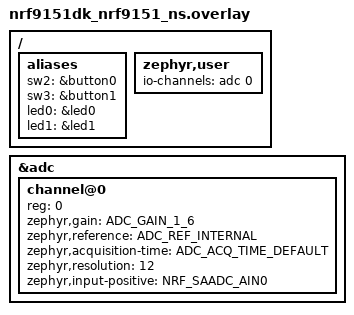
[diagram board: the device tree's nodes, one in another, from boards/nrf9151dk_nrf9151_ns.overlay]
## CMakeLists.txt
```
cmake_minimum_required(VERSION 3.20.0)
find_package(Zephyr REQUIRED HINTS $ENV{ZEPHYR_BASE})

project(iot_Celluar_proj)

target_sources(app 
    PRIVATE 
        src/main.c
        src/socket_setup.c
        src/coap_client.c
        src/modem_lte.c
        src/gnss.c
        src/agnss.c
        src/nodecore_lib/nodecore_event.c
        src/adc_input.c
    )
```

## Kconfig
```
menu "Cellular Project"

config COAP_SERVER_HOSTNAME
    string "CoAP server hostname"

config COAP_SERVER_PORT
    int "CoAP server port"
    default 5683

config FIRMARE_VERSION
    string "Firmware version"
    default "1.0.0"


config COAP_TX_RESOURCE
    string "CoAP resource - this is the TX channel of the board"
    default "large-update"

config COAP_RX_RESOURCE
    string "CoAP resource - this is the RX channel of the board"
    default "validate"

config COAP_DEVICE_ID
    int "CoAP device id - To know which sensor is speaking"
    default 200001

# - Define PSK Identity configurations
config COAP_DEVICE_NAME
    string "Device resource name - this will be the device name on the CoAP server"
    default "cali.test.nrf91"

config COAP_SERVER_PSK
    string "Server PSK"
    default "2e666f726e69756d"

config DK
	bool "nRF9151 DK, nRF9161 DK or nRF9160 DK"
	default y if (BOARD_NRF9160DK_NRF9160_NS) || (BOARD_NRF9161DK_NRF9161_NS) || (BOARD_NRF9151DK_NRF9151_NS)

config THINGY
	bool "Thingy:91 X or Thingy:91"
	default y if (BOARD_THINGY91_NRF9160_NS) || (BOARD_THINGY91X_NRF9151_NS)


config GNSS_PERIODIC_INTERVAL
    int "Fix interval for periodic GPS fixes"
    range 10 65535
    default 15
    help
        Fix interval (in secounds) for periodic fixes.

config DTLS_SEC_TAG
    int "Indicate where the sec tag is and so the modem knows"
    default 12

config GNSS_PERIODIC_TIMEOUT
    int "Fix timeout for periodic GPS fixes"
    range 0 65535
    default 120
    help
       Fix timeout (in secounds) for periodic fixes.
       If set to zero, GNSS is allowed to run indefinietly unttil a valid PVT estimate is produced.

endmenu

menu "Zephyr Kernel"
source "Kconfig.zephyr"
endmenu
```

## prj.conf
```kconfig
# Logging
CONFIG_LOG=y

# Button and LED support
CONFIG_DK_LIBRARY=y

# Newlib
CONFIG_NEWLIB_LIBC=y

# Network
CONFIG_NETWORKING=y
CONFIG_NET_NATIVE=n
CONFIG_NET_SOCKETS=y
CONFIG_NET_SOCKETS_OFFLOAD=y
CONFIG_POSIX_API=y

# Memory
CONFIG_HEAP_MEM_POOL_SIZE=19000
CONFIG_MAIN_STACK_SIZE=8192
CONFIG_SYSTEM_WORKQUEUE_STACK_SIZE=8192

# Modem library
# Enable the nRF Modem library
CONFIG_NRF_MODEM_LIB=y

# Enable the LTE link controller library
CONFIG_LTE_LINK_CONTROL=y

# AT Host library 
CONFIG_AT_HOST_LIBRARY=y

# Enables interrupt support for UART, that the AT Host library can print asynchronously to the console.
CONFIG_UART_INTERRUPT_DRIVEN=y

# Enable this 2 enable printing floating-point numbers to console.
CONFIG_NEWLIB_LIBC_FLOAT_PRINTF=y
CONFIG_FPU=y

#----------------------------------- CoAP ---------------------------------------------------------------
# Enable the CoAP library
CONFIG_COAP=y

# Configure the CoAP server hostname
CONFIG_COAP_SERVER_HOSTNAME="188.149.134.45" #publika hemma

# Configure the CoAP server port
CONFIG_COAP_SERVER_PORT=5683

# Enable the modem’s network mode for GPS --------------------------------------------------------------------------- 
CONFIG_LTE_NETWORK_MODE_LTE_M_GPS=y

# Enable eDRX and PSM
CONFIG_LTE_LC_EDRX_MODULE=y
CONFIG_LTE_LC_PSM_MODULE=y

# enable requesitng the use of eDRX
CONFIG_LTE_EDRX_REQ=y

# Requesting periodic TAU of 8 hours and an active time of 16 seconds.
CONFIG_LTE_PSM_REQ_RPTAU="00101000"
CONFIG_LTE_PSM_REQ_RAT="00001000"

# Enable NRF cloud
CONFIG_NRF_CLOUD=y
CONFIG_NRF_CLOUD_AGNSS=y
CONFIG_NRF_CLOUD_COAP=y

# Required by nRF Cloud A-GNSS
CONFIG_MODEM_INFO=y
CONFIG_MODEM_INFO_ADD_NETWORK=y
CONFIG_MODEM_INFO_ADD_DEVICE=y

# Required for nRF Cloud CoAP authentication/JWT
CONFIG_MODEM_JWT=y
CONFIG_MODEM_KEY_MGMT=y
CONFIG_NRF_CLOUD_CLIENT_ID_SRC_INTERNAL_UUID=y
CONFIG_NRF_CLOUD_CHECK_CREDENTIALS=y
CONFIG_NRF_CLOUD_SEC_TAG=16842753

# Time for JWT / nRF Cloud
CONFIG_DATE_TIME=y
CONFIG_DATE_TIME_NTP=y

# CoAP client settings for nRF Cloud CoAP
CONFIG_COAP_CLIENT_BLOCK_SIZE=1024
CONFIG_COAP_CLIENT_STACK_SIZE=6144
CONFIG_COAP_CLIENT_THREAD_PRIORITY=0
CONFIG_COAP_EXTENDED_OPTIONS_LEN_VALUE=40

CONFIG_COAP_DEVICE_ID=200001
CONFIG_ADC=y

# Aktivera PDN-biblioteket och tillåt äldre PCO-hantering för ditt Conexa-SIM
CONFIG_PDN=y
CONFIG_PDN_LEGACY_PCO=y

# Gör att modemet skickar detaljerade felhändelser (som EMM-koder) till din C-kod
CONFIG_LTE_LC_MODEM_EVENTS_MODULE=y

# Tvinga modemet att använda ditt SIM-korts specifika APN vid registrering
CONFIG_PDN_DEFAULTS_OVERRIDE=y
CONFIG_PDN_DEFAULT_APN="eapn1.net"

# Aktivera nätverks- och bandkonfiguration
CONFIG_LTE_LINK_CONTROL=y

# Korrekt binär bit-sträng för Band 3, 8 och 20 (räknat från höger till vänster)
CONFIG_LTE_LOCK_BANDS=y
CONFIG_LTE_LOCK_BAND_MASK="10000000000010000100"
```

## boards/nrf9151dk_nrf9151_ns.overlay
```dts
#include <zephyr/dt-bindings/adc/adc.h>
#include <zephyr/dt-bindings/adc/nrf-saadc.h>

/ {
    aliases {
        sw2 = &button0;
        sw3 = &button1;

        led0 = &led0;
        led1 = &led1;
    };

    zephyr,user {
        io-channels = <&adc 0>;
    };
};

&adc {
    status = "okay";
    #address-cells = <1>;
    #size-cells = <0>;

    channel@0 {
        reg = <0>;
        zephyr,gain = "ADC_GAIN_1_6";
        zephyr,reference = "ADC_REF_INTERNAL";
        zephyr,acquisition-time = <ADC_ACQ_TIME_DEFAULT>;
        zephyr,resolution = <12>;
        zephyr,input-positive = <NRF_SAADC_AIN0>;
    };
};
```

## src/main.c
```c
#include <stdio.h>
#include <ncs_version.h>

#include <zephyr/kernel.h>
#include <zephyr/logging/log.h>
#include <dk_buttons_and_leds.h>
#include "./nodecore_lib/nodecore_event.h"

#include <zephyr/random/random.h>
#include <zephyr/net/coap.h>
#include "socket_setup.h"
#include "coap_client.h"
#include "modem_lte.h"
#include "app_state.h"
#include "gnss.h"
#include "adc_input.h"

// #define TX_KEEP_ALIVE_INTERVAL 6500

LOG_MODULE_REGISTER(app, LOG_LEVEL_INF);

#define DEVICE_HEALTH_INTERVAL K_SECONDS(120)
#define DEVICE_LIFECYCLE_INTERVAL K_SECONDS(120)

#define DEVICE_STATUS_JSON_SIZE 256


app_state_t app_state = APP_STATE_INIT;

static uint8_t recv_buf[MESSAGE_SIZE];

static struct k_work_delayable device_health_work;
static struct k_work_delayable device_lifecycle_work;

static int32_t filtered_battery_mv = 0;

void device_health_start() {
    k_work_reschedule(&device_health_work, DEVICE_HEALTH_INTERVAL);
}

void device_lifecycle_start() {
    k_work_reschedule(&device_lifecycle_work, DEVICE_LIFECYCLE_INTERVAL);
}


void device_health_handler(struct k_work *work) {
        
        ARG_UNUSED(work);
        
        int err;

         // Läs den råa spänningen från ADC
        int32_t real_battery_mv = read_voltage_mv();

        if (real_battery_mv > 0) {
                if (filtered_battery_mv == 0) {
                // Första körningen någonsin: Sätt startvärdet direkt
                filtered_battery_mv = real_battery_mv;
                } else {
                // 2. TRÖGARE EMA-FILTER: 95% gammal spänning, 5% ny spänning
                // Detta kräver runt 15-20 mätningar för att flytta sig stort, 
                // vilket helt raderar ut spänningsfall från modemsändningar!
                filtered_battery_mv = ((filtered_battery_mv * 95) + (real_battery_mv * 5)) / 100;
                }
        }

        // Skicka in den globala, filtrerade spänningen
        uint8_t battery_percent = calculate_battery_percentage(filtered_battery_mv);
        // Valfritt: Lägg till en logg så du ser hur filtret jobbar i terminalen
        LOG_INF("Rå: %d mV | Filtrerad: %d mV -> %d%%", 
            real_battery_mv, filtered_battery_mv, battery_percent);

        size_t url_path_array_length = 2;
        const char* url_path_array[] = {"device", "health"};


        char text[DEVICE_STATUS_JSON_SIZE];

        int len = snprintf(
                text,
                sizeof(text),
                "{\"device_ID\": %d, \"battery_percent\": %d, \"firmware_version\": \"%s\"}",
                CONFIG_COAP_DEVICE_ID,
                battery_percent,
                CONFIG_FIRMARE_VERSION
        );

        if (len < 0 || len >= sizeof(text)) {
                LOG_ERR("Failed to format device status JSON");
                return;
        }

        LOG_INF("Device health payload: %s", text);
        LOG_INF("Device health payload length: %d", len);


        err = client_post_send((const uint8_t *)text, url_path_array, url_path_array_length);

        if(err != 0) {
                LOG_ERR("Error sendning device health!");
                return;
        }
        LOG_INF("Device health sended!");
        k_work_reschedule(&device_health_work, DEVICE_HEALTH_INTERVAL);
}


void device_lifecycle_handler(struct k_work *work) {
        
        ARG_UNUSED(work);
        
        int err;

        int32_t real_battery_mv = read_voltage_mv();
        uint8_t battery_percent = calculate_battery_percentage(real_battery_mv);
        // uint8_t battery_percent = 93;
                // LOG_INF("Faktisk batterispanning: %d mV (%d%%)", real_battery_mv, battery_percent);

        size_t url_path_array_length = 2;
        const char* url_path_array[] = {"device", "lifecycle"};


        char text[DEVICE_STATUS_JSON_SIZE];

        int len = snprintf(
                text,
                sizeof(text),
                "{\"device_ID\": %d, \"battery_percent\": %d, \"gnss_periodic_timeout\": %d, \"gnss_periodic_interval\": %d, \"firmware_version\": \"%s\"}",
                CONFIG_COAP_DEVICE_ID,
                battery_percent,
                CONFIG_GNSS_PERIODIC_TIMEOUT,
                CONFIG_GNSS_PERIODIC_INTERVAL,
                CONFIG_FIRMARE_VERSION
        );

        if (len < 0 || len >= sizeof(text)) {
                LOG_ERR("Failed to format device status JSON");
                return;
        }

        LOG_INF("Device lifecycle payload: %s", text);
        LOG_INF("Device lifecycle payload length: %d", len);


        err = client_post_send((const uint8_t *)text, url_path_array, url_path_array_length);

        if(err != 0) {
                LOG_ERR("Error sendning device lifecycle!");
                return;
        }
        LOG_INF("Device lifecycle sended!");
        k_work_reschedule(&device_lifecycle_work, DEVICE_LIFECYCLE_INTERVAL);
}

static void button_handler(uint32_t button_state, uint32_t has_changed)
{
       if(has_changed & DK_BTN1_MSK && button_state & DK_BTN1_MSK) {
                size_t url_path_array_length = 2;
                const char* url_path_array[] = {"device", "status"};

                const char text[] = "{\"status\": 1}";

                client_post_send(text, url_path_array, url_path_array_length);
        }
        
        if(has_changed & DK_BTN2_MSK && button_state & DK_BTN2_MSK) {
               
        }

}

int main(void)
{
        int err;
        int recieved;

        err = init_adc();
        if(err < 0) {
                LOG_ERR("init adc failed!");
                return -1;
        }
        LOG_INF("adc initiazled successful!");

        if (dk_leds_init() != 0) {
		LOG_ERR("Failed to initialize the LEDs Library");
                return 0;
	}

        err = modem_configure();
        if(err) {
                LOG_ERR("Failed to configure modem");
                return 0;
        }
        
        if(app_state == APP_STATE_LTE_READY) {
                dk_set_led_on(DK_LED2);
        }

        err = lte_lc_func_mode_set(LTE_LC_FUNC_MODE_ACTIVATE_GNSS);
        if(err) {
                LOG_ERR("Failed to set modem mode!");
                return 0;
        }

               if(dk_buttons_init(button_handler) != 0) {
                LOG_ERR("Failted to init buttons library");
                return 0;
        }

        if(server_resolve() != 0) {
                LOG_INF("Failted to resolve server name");
                return 0;
        }

        if(client_init() != 0) {
                LOG_INF("failed to initialize client");
                return 0;
        }
        
        nodecore_send_event(
                CONFIG_COAP_DEVICE_ID,
                "device_cellular_ready",
                "info",
                "Device cellular connection and backend communication are ready",
                "cellular",
                CONFIG_FIRMARE_VERSION
        );

        k_sleep(K_MSEC(1000));

        LOG_INF("setting GNSS handler");
        if(nrf_modem_gnss_event_handler_set(gnss_event_handler) != 0)
        {
                LOG_ERR("Failed to set gnns event handler!");
                return 0;
        }

        if(nrf_modem_gnss_fix_interval_set(CONFIG_GNSS_PERIODIC_INTERVAL) != 0) {
                LOG_ERR("Failed to set gnss fix interal");
                return 0;
        }

        if(nrf_modem_gnss_fix_retry_set(CONFIG_GNSS_PERIODIC_TIMEOUT) != 0) {
                LOG_ERR("Failed to set gnss retry");
                return 0;
        }

        err = agnss_init();
        if (err) {
                LOG_ERR("Failed to init A-GNSS");
                return 0;
        }

        LOG_INF("Starting GNSS");
        if(nrf_modem_gnss_start() != 0) {
                nodecore_send_event(CONFIG_COAP_DEVICE_ID, "gnss_init_failed", "error", "Failed to initialize gnss", "cellular", CONFIG_FIRMARE_VERSION);
                LOG_ERR("Failed to start GNSS");
                return 0;
        }

        nodecore_send_event(CONFIG_COAP_DEVICE_ID, "gnss_init_success", "info", "Successfully initialized gnss",  "cellular", CONFIG_FIRMARE_VERSION);

        LOG_INF("MAIN: after GNSS start");
        gnss_start_time = k_uptime_get();
 
        LOG_INF("Press button 1 on your DK to (POST) send your if got gps data");
        LOG_INF("Press button 2 on your DK to (GET) get validate data");


        // k_work_init_delayable(&device_health_work, device_health_handler);
        // k_work_submit(&device_health_work);
        // device_health_start();

        k_work_init_delayable(&device_lifecycle_work, device_lifecycle_handler);
        k_work_submit(&device_lifecycle_work);
        device_lifecycle_start();
        

//        char device_id_str[16];

//         snprintk(device_id_str, sizeof(device_id_str), "%d", CONFIG_COAP_DEVICE_ID);

//         const char *url_path_array[] = {
//                 "device",
//                 "firmware_command",
//                 device_id_str
//         };

//         if (client_get_send(url_path_array, ARRAY_SIZE(url_path_array)) != 0) {
//                 LOG_ERR("ERROR GET REQUEST");
//                 return -1;
//         }

        while(true) {

                // 1. ÄNDRING HÄR: Lägg till MSG_DONTWAIT så att recv() inte blockerar tråden
                int received = recv(sock, coap_buf, sizeof(coap_buf), MSG_DONTWAIT);

                if (received < 0) {
                        // errno == EAGAIN eller EWOULDBLOCK betyder bara att det inte fanns någon data att läsa just nu
                        if (errno != EAGAIN && errno != EWOULDBLOCK) {
                                LOG_ERR("Socket error: %d, exit", errno);
                                return -1;
                        }
                } else if (received == 0) {
                        LOG_ERR("Empty datagram");
                        return -1;
                } else {
                        // Vi tog faktiskt emot ett svar från servern! Hantera det.
                        err = client_handle_response(coap_buf, received);
                        if (err < 0) {
                                LOG_ERR("Invalid response, exit");
                                return -1;
                        }
                }
        
               // 2. Om GPS-modulen har sparat ny fix – skicka iväg den direkt!
                if(is_gnss_data_stored == true) {
                        dk_set_led_on(DK_LED1);
                        LOG_INF("POST payload: %s", gps_data);
                        LOG_INF("POST payload length: %d", strlen((char *)gps_data));
                        
                        size_t url_path_array_length = 2;
                        const char* url_path_array[] = {"sensor_data", "gps"};

                        if(client_post_send(gps_data, url_path_array, url_path_array_length) != 0) {
                                LOG_ERR("Failed to send gps data");
                                nodecore_send_event(
                                        CONFIG_COAP_DEVICE_ID,
                                        "gnss_post_failed",
                                        "error",
                                        "cellular",
                                        "Failed to send GNSS position to CoAP server",
                                        CONFIG_FIRMARE_VERSION
                                );
                        }
                        
                        // KORRIGERING 2: Vi sätter bara flaggan till false och går vidare.
                        // Serverns CoAP-svar kommer att fångas upp elegant av "MSG_DONTWAIT"-mottagaren högst upp på nästa varv!
                        is_gnss_data_stored = false;      
                }

                k_sleep(K_MSEC(50));
        }

        close(sock);
        return 0;
}
```

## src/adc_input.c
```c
#include "adc_input.h"

#include <zephyr/logging/log.h>

LOG_MODULE_DECLARE(app, LOG_LEVEL_INF);

#if !DT_NODE_EXISTS(DT_PATH(zephyr_user)) || \
	!DT_NODE_HAS_PROP(DT_PATH(zephyr_user), io_channels)
#error "No suitable devicetree overlay specified"
#endif

#define DT_SPEC_AND_COMMA(node_id, prop, idx) \
	ADC_DT_SPEC_GET_BY_IDX(node_id, idx),

/* Data of ADC io-channels specified in devicetree. */
static const struct adc_dt_spec adc_channels[] = {
	DT_FOREACH_PROP_ELEM(DT_PATH(zephyr_user), io_channels,
			     DT_SPEC_AND_COMMA)
};

int init_adc(void) {
    if (!adc_is_ready_dt(&adc_channels[0])) {
        return -1;
    }
    return adc_channel_setup_dt(&adc_channels[0]);
}

int32_t read_voltage_mv(void) {
    uint16_t buf;
    int32_t val_mv;
    struct adc_sequence sequence = {
        .buffer = &buf,
        .buffer_size = sizeof(buf),
    };

    adc_sequence_init_dt(&adc_channels[0], &sequence);
    
    int err = adc_read_dt(&adc_channels[0], &sequence);
    if (err < 0) return err;

    val_mv = (int32_t)buf;
    err = adc_raw_to_millivolts_dt(&adc_channels[0], &val_mv);
    
    int32_t real_battery_mv = val_mv * 2;


    // ... efter real_battery_mv beräkningen ...
    LOG_INF("ADC rå-mv på pinne: %d mV | Beräknad batterispänning: %d mV", val_mv, real_battery_mv);
    return (err < 0) ? err : real_battery_mv;
}


uint8_t calculate_battery_percentage(int32_t mvolts) {
    // Definiera brytpunkterna för spänning (mV) och motsvarande procent (%)
    // Dessa matchar ett typiskt 4x AA-batteripack under belastning
    static const int32_t volt_pts[] = {6000, 5200, 4800, 4400, 4000, 3600};
    static const int32_t pct_pts[]  = {100,  80,   60,   40,   15,   0};
    static const int num_pts = sizeof(volt_pts) / sizeof(volt_pts[0]);

    // Om spänningen är högre än vår max-punkt
    if (mvolts >= volt_pts[0]) {
        return (uint8_t)pct_pts[0];
    }
    
    // Om spänningen är lägre än vår min-punkt (helt urladdat)
    if (mvolts <= volt_pts[num_pts - 1]) {
        return (uint8_t)pct_pts[num_pts - 1];
    }

    // Hitta vilket intervall spänningen ligger mellan
    for (int i = 0; i < num_pts - 1; i++) {
        if (mvolts >= volt_pts[i + 1]) {
            // Vi har hittat rätt intervall! 
            // volt_pts[i] är den högre spänningen, volt_pts[i+1] är den lägre.
            int32_t v_high = volt_pts[i];
            int32_t v_low  = volt_pts[i + 1];
            int32_t p_high = pct_pts[i];
            int32_t p_low  = pct_pts[i + 1];

            // Räkna ut exakt var inom detta specifika intervall vi befinner oss (linjärt)
            int32_t percentage = p_low + ((mvolts - v_low) * (p_high - p_low)) / (v_high - v_low);
            
            return (uint8_t)percentage;
        }
    }

    return 0; // Fallback
}
```

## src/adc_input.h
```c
#pragma once

#include <zephyr/drivers/adc.h>
#include <zephyr/devicetree.h>


#include <stdint.h>

/* Initierar ADC-hårdvaran baserat på devicetree */
int init_adc(void);

/* Läser av spänningen och returnerar värdet i millivolt (mV) */
int32_t read_voltage_mv(void);
uint8_t calculate_battery_percentage(int32_t mvolts);
```

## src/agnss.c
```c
#include "agnss.h"
#include <string.h>

#include <zephyr/kernel.h>
#include <zephyr/logging/log.h>
#include <net/nrf_cloud_coap.h>
#include <net/nrf_cloud_agnss.h>
#include <net/nrf_cloud_rest.h>

static struct k_work agnss_request_work;
static struct nrf_modem_gnss_agnss_data_frame stored_agnss_req;

LOG_MODULE_DECLARE(app, LOG_LEVEL_INF);

static char agnss_buf[NRF_CLOUD_AGNSS_MAX_DATA_SIZE];
static void agnss_work(struct k_work *work) {
    int err;
    ARG_UNUSED(work);

    LOG_INF("A-GNSS work running");
    LOG_INF("A-GNSS data_flags: 0x%02x", stored_agnss_req.data_flags);
    LOG_INF("A-GNSS system_count: %d", stored_agnss_req.system_count);

    /*
        * Nästa steg senare:
        * 1. Skicka stored_agnss_req till nRF Cloud CoAP
        * 2. Få tillbaka A-GNSS data
        * 3. Injecta med nrf_cloud_agnss_process()
        */
    struct nrf_cloud_rest_agnss_request request = {
            .type = NRF_CLOUD_REST_AGNSS_REQ_CUSTOM,
            .agnss_req = &stored_agnss_req,
            .net_info = NULL,
            .filtered = false,
            .mask_angle = NRF_CLOUD_AGNSS_MASK_ANGLE_NONE,
    };

    struct nrf_cloud_rest_agnss_result result = {
            .buf = agnss_buf,
            .buf_sz = sizeof(agnss_buf),
            .agnss_sz = 0,
    };

    LOG_INF("Requesting A-GNSS data from nRF Cloud");

    err = nrf_cloud_coap_agnss_data_get(&request, &result);
    if (err) {
            LOG_ERR("nrf_cloud_coap_agnss_data_get failed: %d", err);
            return;
    }

    LOG_INF("A-GNSS data received: %d bytes", result.agnss_sz);

    err = nrf_cloud_agnss_process(result.buf, result.agnss_sz);
    if (err) {
            LOG_ERR("nrf_cloud_agnss_process failed: %d", err);
            return;
    }

    LOG_INF("A-GNSS data injected into modem");
}

int agnss_init(void)
{
        int err;

        k_work_init(&agnss_request_work, agnss_work);

        LOG_INF("Initializing nRF Cloud CoAP");

        err = nrf_cloud_coap_init();
        if (err) {
                LOG_ERR("nrf_cloud_coap_init failed: %d", err);
                return err;
        }

        LOG_INF("Connecting to nRF Cloud CoAP");

        err = nrf_cloud_coap_connect(NULL);
        if (err) {
                LOG_ERR("nrf_cloud_coap_connect failed: %d", err);
                return err;
        }

        LOG_INF("nRF Cloud CoAP connected");
        LOG_INF("A-GNSS work initialized");

        return 0;
}
 
void agnss_request_schedule(
        const struct nrf_modem_gnss_agnss_data_frame *req
)
{
        if (req == NULL) {
                LOG_ERR("A-GNSS request was NULL");
                return;
        }

        memcpy(&stored_agnss_req, req, sizeof(stored_agnss_req));

        k_work_submit(&agnss_request_work);

        LOG_INF("A-GNSS work scheduled");
}
```

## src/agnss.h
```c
#ifndef AGNSS_H_
#define AGNSS_H_

#include <nrf_modem_gnss.h>

// init the work
int agnss_init(void);


// Storing the local variable in modem and then submitting the work to run
void agnss_request_schedule(
        const struct nrf_modem_gnss_agnss_data_frame *req
);

#endif
```

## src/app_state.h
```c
#pragma once

typedef enum {
    APP_STATE_INIT,
    APP_STATE_LTE_READY,
    APP_STATE_COAP_READY,
    APP_STATE_GNSS_RUNNING,
    APP_STATE_READY
} app_state_t;

extern app_state_t app_state;
```

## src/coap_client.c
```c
#include "coap_client.h"

LOG_MODULE_DECLARE(app, LOG_LEVEL_INF);

// Ersätt eller lägg till vid dina globala variabler i coap_client.c:
static uint16_t last_post_token = 0;
static uint16_t last_get_token  = 0;


int client_put_send() {
        int err;
        struct coap_packet request;

        err = coap_packet_init(&request, coap_buf, sizeof(coap_buf), APP_COAP_VERSION, COAP_TYPE_NON_CON, sizeof(next_token), (uint8_t*)&next_token, COAP_METHOD_PUT, coap_next_id());
        if(err < 0) {
                LOG_ERR("Failted to send CoAP request, %d", errno);
                return errno;
        }

        err = coap_packet_append_option(&request, COAP_OPTION_URI_PATH, (uint8_t*)&CONFIG_COAP_TX_RESOURCE, strlen(CONFIG_COAP_TX_RESOURCE));
        if(err < 0) {
                LOG_ERR("Failed to encode CoAP option, %d", err);
	        return err; 
        }

        const uint8_t json_format = COAP_CONTENT_FORMAT_TEXT_PLAIN;

        err = coap_packet_append_option(&request, COAP_OPTION_CONTENT_FORMAT, &json_format, sizeof(json_format));
        if(err < 0) {
                LOG_ERR("Failed to append CoAP option, %d", err);
	        return err; 
        }

        err = coap_packet_append_payload_marker(&request);
        if(err < 0) {
                LOG_ERR("Failed to append payload marker: %d", err);
                return err;
        }

        err = coap_packet_append_payload(&request, (uint8_t*)MESSAGE_TO_SEND, sizeof(MESSAGE_TO_SEND));
        if(err < 0) {
                LOG_ERR("Failed to append payload: %d", err);
                return err;
        }

        /*
                Det är i detta request packet vi har packeterat vårt meddalnde i property data
                Sedan i offset finns längden på den 
        */
        err = send(sock, request.data, request.offset, 0);

        if(err < 0) {
                LOG_ERR("Failed to send CoAP request, %d", errno);
                return errno;
        }

        LOG_INF("CoAP PUT request sent: Token: 0x%04x", next_token);

        return 0;
}

int client_get_send(const char *url_path_array[], size_t url_path_array_length)
{
        int err;
        struct coap_packet request;
        uint8_t tx_buf[512];
        
        // --- ANVÄND GET-TOKEN HÄR ---
        last_get_token = sys_rand32_get() & 0xFFFF;

        err = coap_packet_init(
                &request,
                tx_buf,
                sizeof(tx_buf),
                APP_COAP_VERSION,
                COAP_TYPE_CON,
                sizeof(last_get_token),
                (uint8_t *)&last_get_token, // Skicka med GET-token
                COAP_METHOD_GET,
                coap_next_id()
        );

        if (err < 0) {
                LOG_ERR("Failed to create CoAP GET request: %d", err);
                return err;
        }

        LOG_INF("Building CoAP GET path:");
        for (size_t i = 0; i < url_path_array_length; i++) {
                LOG_INF("Path[%d]: %s", i, url_path_array[i]);
                err = coap_packet_append_option(
                        &request,
                        COAP_OPTION_URI_PATH,
                        (const uint8_t *)url_path_array[i],
                        strlen(url_path_array[i])
                );
                if (err < 0) return err;
        }

        LOG_INF("CoAP GET packet size: %d bytes", request.offset);
        err = send(sock, request.data, request.offset, 0);

        if (err < 0) {
                LOG_ERR("Failed to send CoAP GET request, errno: %d", errno);
                return errno;
        }

        LOG_INF("send() returned: %d bytes", err);
        LOG_INF("CoAP GET request sent: Token: 0x%04x", last_get_token);

        return 0;
}


int client_post_send(const uint8_t *payload, const char* url_path_array[],  size_t url_path_array_length) 
{
        int err;
        struct coap_packet request;
        uint8_t tx_buf[512];

        // --- ANVÄND POST-TOKEN HÄR ---
        last_post_token = sys_rand32_get() & 0xFFFF;

        err = coap_packet_init(&request, tx_buf, sizeof(tx_buf), APP_COAP_VERSION, COAP_TYPE_CON, sizeof(last_post_token), (uint8_t*)&last_post_token, COAP_METHOD_POST, coap_next_id());
        if(err < 0) {
                LOG_ERR("Failed to send CoAP request, %d", errno);
                return errno;
        }

        for(size_t i = 0; i < url_path_array_length; i++) {
             err = coap_packet_append_option(&request, COAP_OPTION_URI_PATH, (const uint8_t *)url_path_array[i], strlen(url_path_array[i]));
             if (err < 0) return err;   
        }
        
        const uint8_t json_format = COAP_CONTENT_FORMAT_APP_JSON;
        err = coap_packet_append_option(&request, COAP_OPTION_CONTENT_FORMAT, &json_format, sizeof(json_format));
        if(err < 0) return err; 

        err = coap_packet_append_payload_marker(&request);
        if(err < 0) return err;

        err = coap_packet_append_payload(&request, payload, strlen((char*)payload));
        if(err < 0) return err;

        LOG_INF("Sending payload len: %d", strlen((char *)payload));
        err = send(sock, request.data, request.offset, 0);

        if(err < 0) {
                LOG_ERR("Failed to send CoAP request, %d", errno);
                return errno;
        }

        LOG_INF("CoAP POST request sent: Token: 0x%04x", last_post_token);
        return 0;
}

int client_handle_response(uint8_t *buf, int received) 
{
        struct coap_packet reply;
        const uint8_t *payload;
        uint16_t payload_len;
        uint8_t temp_buf[256];
        uint8_t token[8];

        int err = coap_packet_parse(&reply, buf, received, NULL, 0); 
        if(err < 0) {
                LOG_ERR("Malformed response recieved: %d", err);
                return err;
        }

        // --- 1. HANTERA TOMMA MEDDELANDEN (Svar på Token 0x0000-varningen) ---
        uint8_t msg_code = coap_header_get_code(&reply);
        if (msg_code == 0) { // 0.00 Empty Message (ACK)
                LOG_INF("Received Empty CoAP ACK/Ping from server (MID: %d)", coap_header_get_id(&reply));
                return 0; // Det är bara ett nätverkskvitto, avbryt här utan fel.
        }

        // --- 2. SKICKA ACK OM SERVERNS SVAR ÄR "CON" (Svar på återutsändnings-varningarna) ---
        uint8_t msg_type = coap_header_get_type(&reply);
        if (msg_type == COAP_TYPE_CON) {
                struct coap_packet ack_pkt;
                uint8_t ack_buf[16];
                uint16_t mid = coap_header_get_id(&reply);

                // Skapa ett tomt ACK-paket med samma Message ID (mid) som servern skickade
                int ack_err = coap_packet_init(&ack_pkt, ack_buf, sizeof(ack_buf),
                                               APP_COAP_VERSION, COAP_TYPE_ACK,
                                               0, NULL, 0, mid);
                if (ack_err >= 0) {
                        send(sock, ack_pkt.data, ack_pkt.offset, 0);
                        LOG_INF("Sent CoAP ACK back to server for MID: %d", mid);
                } else {
                        LOG_ERR("Failed to initialize ACK packet: %d", ack_err);
                }
        }

        // --- 3. TOKEN-VALIDERING ---
        uint16_t token_len = coap_header_get_token(&reply, token); 
        uint16_t received_token = 0;
        if (token_len == 2) {
                received_token = (token[1] << 8) | token[0];
        }

        if (received_token != last_get_token && received_token != last_post_token) {  
                LOG_ERR("Invalid token recieved: 0x%04x (Expected GET: 0x%04x or POST: 0x%04x)", 
                        received_token, last_get_token, last_post_token);
                return 0; 
        }

        // Hämta payload
        payload = coap_packet_get_payload(&reply, &payload_len);

        if (payload_len > 0 && payload != NULL) {
                size_t copy_len = MIN(payload_len, sizeof(temp_buf) - 1);
                memcpy(temp_buf, payload, copy_len);
                temp_buf[copy_len] = '\0';
        } else {
                strcpy((char *)temp_buf, "EMPTY");
        }
        
        LOG_INF("Response payload len: %d", payload_len);
        LOG_INF("CoAP response: Code 0x%x, Payload: %s", coap_header_get_code(&reply), (char*)temp_buf);
        
        // --- 4. DIN LOGIK FÖR ATT AGERA PÅ SVARET ---
        if (received_token == last_get_token) {
                LOG_INF(">>> This is a response to our GET request!");
                bool is_modem_info = true;
                char json_buffer[512]; // Denna buffer måste vara stor nog att rymma hela JSON-texten

                
                if (strstr((char*)temp_buf, "\"command\":\"diagnostic\"") != NULL) {
                        LOG_INF("Diagnostic command found! Let's do something...");
                        // HÄR KAN DU KÖRA DIN DIAGNOSTIK-FUNKTION!
                        diagnostic_data_t diag_report = {0};

                        // En temporär buffer för att hämta rå-RSRP-strängen från modemet
                        char temp_rsrp[32];

                        if (modem_info_string_get(MODEM_INFO_RSRP, temp_rsrp, sizeof(temp_rsrp)) < 0) {
                                LOG_ERR("Failed to get RSRP info!");
                                is_modem_info = false;   
                        }
                        // Omvandla index-strängen till ett riktigt dBm-heltal
                        int rsrp_index = atoi(temp_rsrp);
                        int rsrp_dbm = rsrp_index - 140;
                        diag_report.rsrp_dbm = rsrp_dbm;

                        LOG_INF("Signalstyrka: %d dBm", rsrp_dbm);
                        
                        
                        if (modem_info_string_get(MODEM_INFO_CELLID, diag_report.cell_id, sizeof(diag_report.cell_id)) < 0) {
                                LOG_ERR("Failed to get MODEM_INFO_CELLID!");
                                 is_modem_info = false;   
                        }
                        LOG_INF("MODEM_INFO_CELLID: %s", diag_report.cell_id);

                        if (modem_info_string_get(MODEM_INFO_OPERATOR, diag_report.operator, sizeof(diag_report.operator)) < 0) {
                                LOG_ERR("Failed to get MODEM_INFO_OPERATOR!");
                                is_modem_info = false;   
                        }
                        LOG_INF("MODEM_INFO_OPERATOR: %s", diag_report.operator);

                        
                        if(is_modem_info == false) { 
                           int json_len = snprintf(json_buffer, sizeof(json_buffer),
                                "{\"device_ID\":%d,"
                                "\"command_status\":\"failed\","
                                "\"msg\":\"Failed to get modem_info\","
                                "\"payload\":null}", // Allt ligger nu i en och samma sträng, stängs först HÄR!
                                CONFIG_COAP_DEVICE_ID);

                                if (json_len < 0 || json_len >= sizeof(json_buffer)) {
                                        LOG_ERR("JSON buffer was too small!");
                                } else {
                                        LOG_INF("Generated Diagnostic JSON: %s", json_buffer);
                                }

                                // Definiera din URL path: /device/diagnostic
                                size_t url_path_array_length = 2;
                                const char* url_path_array[] = {"device", "firmware_command"};

                                // Skicka iväg paketet!
                                if (client_post_send(json_buffer, url_path_array, url_path_array_length) != 0) {
                                        LOG_ERR("Misslyckades att skicka diagnostikrapporten via CoAP POST");
                                } else {
                                        LOG_INF("Diagnostikrapporten skickad till servern!");
                                }
                                return 0;
                        }
                        else {
                                LOG_INF("MODEM_INFO_IP_ADDRESS: %s", diag_report.ip_address);

                                
                                int32_t real_battery_mv = read_voltage_mv();
                                uint8_t battery_percent = calculate_battery_percentage(real_battery_mv);

                                diag_report.battery_percent = battery_percent;

                                LOG_INF("Faktisk batterispanning: %d mV (%d%%)", real_battery_mv,  diag_report.battery_percent);


                                char json_buffer[256]; // Denna buffer måste vara stor nog att rymma hela JSON-texten

                                char json_buffer_temp[256];
                           
                                
                                

                                int temp_len = snprintf(json_buffer_temp, sizeof(json_buffer_temp),
                                        "{\"rsrp\":%d,"
                                        "\"cell_id\":\"%s\","
                                        "\"operator\":\"%s\","
                                        "\"battery\":%d}",   

                                        diag_report.rsrp_dbm,
                                        diag_report.cell_id,
                                        diag_report.operator,
                                        diag_report.battery_percent
                                );

                                // Kontrollera att steg 1 fick plats
                                if (temp_len < 0 || temp_len >= sizeof(json_buffer_temp)) {
                                        LOG_ERR("Temporary JSON buffer was too small!");
                                }
                                
                                int json_len = snprintf(json_buffer, sizeof(json_buffer),
                                        "{\"device_ID\":%d,"
                                        "\"command_status\":\"success\","
                                        "\"msg\":\"Succeeded to get modem_info from device\","
                                        "\"payload\":%s}", // %s kommer att ersättas med hela json_buffer_temp-texten
                                        CONFIG_COAP_DEVICE_ID,
                                        json_buffer_temp // ÄNDRAT: Skickar strängen, inte längden (siffran)!
                                );

                                  // Kontrollera att slutresultatet fick plats
                                if (json_len < 0 || json_len >= sizeof(json_buffer)) {
                                        LOG_ERR("Main JSON buffer was too small!");
                                } else {
                                        LOG_INF("Generated Diagnostic JSON: %s", json_buffer);
                                }

                                // Definiera din URL path: /device/diagnostic
                                size_t url_path_array_length = 2;
                                const char* url_path_array[] = {"device", "firmware_command"};

                                // Skicka iväg paketet!
                                if (client_post_send(json_buffer, url_path_array, url_path_array_length) != 0) {
                                        LOG_ERR("Misslyckades att skicka diagnostikrapporten via CoAP POST");
                                } else {
                                        LOG_INF("Diagnostikrapporten skickad till servern!");
                                }
                                return 0;

                        }  

                }
                
                last_get_token = 0; 
                
        } else if (received_token == last_post_token) {
                LOG_INF(">>> This is a response to our POST request!");
                last_post_token = 0;
        }

        return 0;
}
```

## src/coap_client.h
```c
#pragma once
#include <zephyr/net/coap.h>
#include <zephyr/logging/log.h>
#include <modem/modem_info.h>
#include <stdlib.h>
#include "adc_input.h"
#include "socket_setup.h"

#define APP_COAP_MAX_MSG_LEN 1280
#define APP_COAP_VERSION 1
#define MESSAGE_TO_SEND "Hi, from dennis board!!!!!"

/*
 char signal_buffer[32];
                        if (modem_info_string_get(MODEM_INFO_RSRP, signal_buffer, sizeof(signal_buffer)) < 0) {
                                LOG_ERR("Failed to get RSRP info!");
                                return -1;
                        }
                        // Omvandla index-strängen till ett riktigt dBm-heltal
                        int rsrp_index = atoi(signal_buffer);
                        int rsrp_dbm = rsrp_index - 140;

                        LOG_INF("MODEM_INFO_RSRP (Rå-index): %s", signal_buffer);
                        LOG_INF("Faktisk signalstyrka: %d dBm", rsrp_dbm);
                        
                        
                        if (modem_info_string_get(MODEM_INFO_CELLID, signal_buffer, sizeof(signal_buffer)) < 0) {
                                LOG_ERR("Failed to get MODEM_INFO_CELLID!");
                                return -1;
                        }
                        LOG_INF("MODEM_INFO_CELLID: %s", signal_buffer);

                        if (modem_info_string_get(MODEM_INFO_OPERATOR, signal_buffer, sizeof(signal_buffer)) < 0) {
                                LOG_ERR("Failed to get MODEM_INFO_OPERATOR!");
                                return -1;
                        }
                        LOG_INF("MODEM_INFO_OPERATOR: %s", signal_buffer);

                        if (modem_info_string_get(MODEM_INFO_IP_ADDRESS, signal_buffer, sizeof(signal_buffer)) < 0) {
                                LOG_ERR("Failed to get MODEM_INFO_IP_ADDRESS!");
                                return -1;
                        }
                        LOG_INF("MODEM_INFO_IP_ADDRESS: %s", signal_buffer);

                        
                        int32_t real_battery_mv = read_voltage_mv();
                        uint8_t battery_percent = calculate_battery_percentage(real_battery_mv);

                        LOG_INF("Faktisk batterispanning: %d mV (%d%%)", real_battery_mv, battery_percent);
*/


typedef struct diagnostic_data_t {
    int rsrp_dbm;
    char cell_id[32];
    char operator[32];
    char ip_address[32];
    uint8_t battery_percent;
} diagnostic_data_t;

// CoAP
static uint8_t coap_buf[APP_COAP_MAX_MSG_LEN];

int client_get_send(const char* url_path_array[],  size_t url_path_array_length);

/**
 * @brief if returning 0 then successful
 * @param payload 
 * @param url_path_array 
 * @param url_path_array_length 
 * @return 
 */


int client_post_send(const uint8_t *payload, const char* url_path_array[],  size_t url_path_array_length);

// NOTE: here if successful we will store the data in gloabal variable coap_buf
int client_put_send();

// Here after we recv from the socket we put the the values in buf and the length of the buf into varible recieved
int client_handle_response(uint8_t *buf, int received);
```

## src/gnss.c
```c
#include "gnss.h"

LOG_MODULE_DECLARE(app);



bool first_fix = false;
bool is_gnss_data_stored = false;
uint8_t gps_data[MESSAGE_SIZE];
int64_t gnss_start_time;
struct nrf_modem_gnss_pvt_data_frame pvt_data;


void print_fix_data(struct nrf_modem_gnss_pvt_data_frame *pvt_data)
{
	LOG_INF("Latitude:       %.06f", pvt_data->latitude);
	LOG_INF("Longitude:      %.06f", pvt_data->longitude);
	LOG_INF("Altitude:       %.01f m", (double)pvt_data->altitude);
	LOG_INF("Time (UTC):     %02u:%02u:%02u.%03u",
	       pvt_data->datetime.hour,
	       pvt_data->datetime.minute,
	       pvt_data->datetime.seconds,
	       pvt_data->datetime.ms);
}

int store_gnss_data(struct nrf_modem_gnss_pvt_data_frame *pvt_data)
{
    int err = snprintf(
        (char *)gps_data,
        sizeof(gps_data),
        "{"
            "\"device_ID\":%d,"
            "\"lat\":%.7f,"
            "\"lon\":%.7f,"
            "\"acc\":%.2f,"
            "\"data_timestamp\":\"%04u-%02u-%02uT%02u:%02u:%02uZ\""
        "}",
        CONFIG_COAP_DEVICE_ID,
        pvt_data->latitude,
        pvt_data->longitude,
        pvt_data->accuracy,
        pvt_data->datetime.year,
        pvt_data->datetime.month,
        pvt_data->datetime.day,
        pvt_data->datetime.hour,
        pvt_data->datetime.minute,
        pvt_data->datetime.seconds
    );

    if (err < 0) {
        LOG_ERR("Failed to print to buffer: %d", err);
        return -1;
    }

    if (err >= sizeof(gps_data)) {
        LOG_ERR("GPS data buffer too small. Needed %d bytes", err + 1);
        return -1;
    }

    LOG_INF("Stored GPS JSON: %s", gps_data);

    return 0;
}

void gnss_event_handler(int event) {
    int err;

    switch(event) {
        case NRF_MODEM_GNSS_EVT_PVT:

                LOG_INF("Searching...");
                err = nrf_modem_gnss_read(&pvt_data, sizeof(pvt_data), NRF_MODEM_GNSS_DATA_PVT);
                if(err < 0) {
                        LOG_ERR("Failed reading the gnss!!");
                        return;
                }

                if(pvt_data.flags & NRF_MODEM_GNSS_PVT_FLAG_DEADLINE_MISSED) {
                        LOG_INF("GNSS blocked by LTE activity");
                }
                if(pvt_data.flags & NRF_MODEM_GNSS_PVT_FLAG_NOT_ENOUGH_WINDOW_TIME) {
                        LOG_INF("Insufficient GNSS time window");
                }

                int num_satellites = 0;
                for (int i = 0; i < 12 ; i++) {
                        if (pvt_data.sv[i].signal != 0) {
                                LOG_INF("sv: %d, cn0: %d", pvt_data.sv[i].sv, pvt_data.sv[i].cn0);
                                num_satellites++;
                        }

                }
                LOG_INF("Number of satellites: %d", num_satellites);

                if(pvt_data.flags & NRF_MODEM_GNSS_PVT_FLAG_FIX_VALID) {
                        print_fix_data(&pvt_data);

                        if(store_gnss_data(&pvt_data) != 0) {
                                LOG_ERR("Failed to store GPS data to global (gps_data)");
                                return;
                        } else {
                                is_gnss_data_stored = true;
                        }
                        

                        if(!first_fix) {
                                first_fix = true;
                                LOG_INF("Time to first fix: %2.1lld s", (k_uptime_get() - gnss_start_time)/1000);
                        }
                        return;
                }

                break;
        case NRF_MODEM_GNSS_EVT_PERIODIC_WAKEUP:
                LOG_INF("GNS wakeing up!");
                break;
        case NRF_MODEM_GNSS_EVT_SLEEP_AFTER_FIX:
                LOG_INF("GNSS got fix, we sleeping...");
                break;
                
        case NRF_MODEM_GNSS_EVT_AGNSS_REQ: {
                struct nrf_modem_gnss_agnss_data_frame agnss_req;

                int err = nrf_modem_gnss_read(
                        &agnss_req,
                        sizeof(agnss_req),
                        NRF_MODEM_GNSS_DATA_AGNSS_REQ
                );

                if (err != 0) {
                        LOG_ERR("Error reading A-GNSS request: %d", err);
                        break;
                }

                LOG_INF("GNSS requested A-GNSS data");

                agnss_request_schedule(&agnss_req);

                break;
        }
            
    }
}
```

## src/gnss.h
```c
#pragma once

#include <nrf_modem_gnss.h>
#include <zephyr/logging/log.h>
#include "app_state.h"

#define MESSAGE_SIZE 256
#define SSTRLEN(s) (sizeof(s) - 1)

extern struct nrf_modem_gnss_pvt_data_frame pvt_data;
extern int64_t gnss_start_time;
extern bool first_fix;
extern bool is_gnss_data_stored;
extern uint8_t gps_data[MESSAGE_SIZE];


/*
    @brief Print the GNSS posistion data into the buffer
*/
void print_fix_data(struct nrf_modem_gnss_pvt_data_frame *pvt_data);

// Function to store the gps location, Accurancy and datetime on global varible gps_data
int store_gnss_data(struct nrf_modem_gnss_pvt_data_frame *pvt_data);


// @brief Handling the diffrent event from the GNSS reciever
void gnss_event_handler(int event);
```

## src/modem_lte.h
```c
#pragma once

#include <modem/nrf_modem_lib.h>
#include <modem/lte_lc.h>
#include <modem/modem_key_mgmt.h>
#include <zephyr/logging/log.h>
#include "agnss.h"
#include "app_state.h"

#define SEC_TAG 12

extern int64_t lte_network_connect_duration;  
int modem_configure(void);
void lte_handler(const struct lte_lc_evt *const evt);
```

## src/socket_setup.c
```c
#include "socket_setup.h"

LOG_MODULE_DECLARE(app, LOG_LEVEL_INF);

int sock = -1;
struct sockaddr_storage server;
uint16_t next_token;

int server_resolve() {
    int err;

    // Getting the actual result and the address info
    struct addrinfo* result;

    // Specifying the address info
    struct addrinfo hints = {
            .ai_family = AF_INET,
            .ai_socktype = SOCK_DGRAM, 
    };

    err = getaddrinfo(CONFIG_COAP_SERVER_HOSTNAME, NULL, &hints, &result);
    if(err != 0) {
            LOG_INF("Failed to get address info");
            return -EIO;
    }

    if(result == NULL) {
            LOG_INF("ERROR: Address not found");
            return -ENOENT;
    }

    struct sockaddr_in* server_addr = (struct sockaddr_in*)&server;
    struct sockaddr_in* addr_temp = (struct sockaddr_in*)result->ai_addr;

    server_addr->sin_addr   = addr_temp->sin_addr;
    server_addr->sin_family = addr_temp->sin_family;
    server_addr->sin_port   = htons(CONFIG_COAP_SERVER_PORT);
    
    // converting network address to string to print it out
    char ipv4_addr[NET_IPV4_ADDR_LEN];
    inet_ntop(AF_INET, &server_addr->sin_addr.s_addr, ipv4_addr, sizeof(ipv4_addr));
    LOG_INF("IPv4 Address found %s", ipv4_addr);

    freeaddrinfo(result); 
    
    return 0;
}

int client_init() {
    int err;

    sock = socket(AF_INET, SOCK_DGRAM, IPPROTO_UDP);
    if(sock < 0) {
            LOG_INF("Connection failed : %d", errno);
            return -errno;
    }
 

    err = connect(sock, (struct sockaddr*)&server, sizeof(struct sockaddr_in));
    if(err < 0) {
            LOG_INF("Connect failed : %d", errno);
            return -errno;
    }
    
    LOG_INF("Successfully connected to the server");
    /* Generate a random token after the socket is connected */
    next_token = sys_rand32_get();

    return 0;
}
```
